# RTC_445 register map
Vendor: Texas Instruments
Peripheral module from a debugger description file (folder msp430).
Registers are 16-bit, access not given, no defined reset value unless marked. A register's access mark holds for its fields unless they carry their own. Offsets are as the file gives them; lines under a group give offsets from that group; [hi:lo] are bit positions; {n}, {i} and the like mark numbered series; 'fields as' and 'values as' point back to an identical list; <NAME> marks a mode.

## RTC
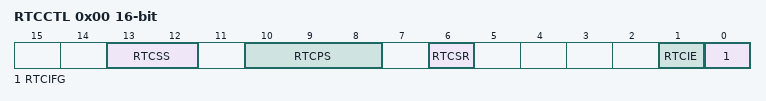
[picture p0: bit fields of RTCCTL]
0x00 RTCCTL access per field — RTCCTL0 Register
  [13:12] RTCSS rw — Real-time clock source select
    0=DISABLED; 1=SMCLK; 2=XT1CLK; 3=VLOCLK
  [10:8] RTCPS rw — Real-time clock pre-divider select
    0=1; 1=10; 2=100; 3=1000; 4=16; 5=64; 6=256; 7=1024
  [6] RTCSR rw — Real-time software reset. This is a write only bit and is always read with logic 0. 0b = Write 0 has no effect
    0=Write 0 has no effect; 1=Write 1 to this bit clears the counter value and reloads the shadow register value from the modulo register at the next tick of the selected source clock. No overflow event or interrupt is generated.
  [1] RTCIE rw — Real-time interrupt enable
    0=Interrupt disabled; 1=Interrupt enabled
  [0] RTCIFG ro — Real-time interrupt flag. This bit reports the status of a pending interrupt. This read only bit can be cleared by reading RTCIV register.
    0=No interrupt pending; 1=Interrupt pending
0x04 RTCIV ro — Real-Time Clock Interrupt Vector Register
  [15:0] RTCIV — Real-time clock interrupt vector value
    0=NONE (No interrupt pending); 2=RTCIFG (upt Source: RTC Counter Overflow; Interrupt Flag: RTCIFG)
0x08 RTCMOD — RTC Counter Modulo Register
0x0C RTCCNT — RTC Counter Register
